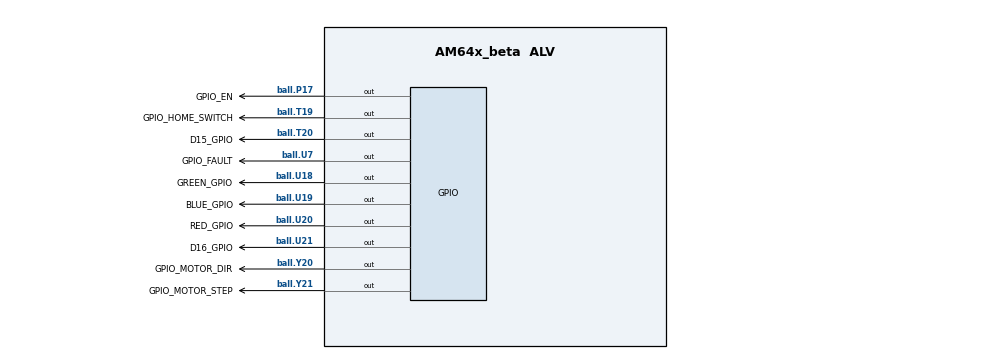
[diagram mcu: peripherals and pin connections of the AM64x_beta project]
/**
 * These arguments were used when this file was generated. They will be automatically applied on subsequent loads
 * via the GUI or CLI. Run CLI with '--help' for additional information on how to override these arguments.
 * @cliArgs --device "AM64x_beta" --package "ALV" --part "Default" --context "r5fss0-0" --product "MCU_PLUS_SDK_AM64x@08.01.00"
 * @versions {"tool":"1.13.0+2553"}
 */

/**
 * Import the modules used in this configuration.
 */
const eeprom     = scripting.addModule("/board/eeprom/eeprom", {}, false);
const eeprom1    = eeprom.addInstance();
const led        = scripting.addModule("/board/led/led", {}, false);
const led1       = led.addInstance();
const led2       = led.addInstance();
const led3       = led.addInstance();
const gpio       = scripting.addModule("/drivers/gpio/gpio", {}, false);
const gpio1      = gpio.addInstance();
const gpio2      = gpio.addInstance();
const gpio3      = gpio.addInstance();
const gpio4      = gpio.addInstance();
const gpio5      = gpio.addInstance();
const gpio6      = gpio.addInstance();
const gpio7      = gpio.addInstance();
const gpio8      = gpio.addInstance();
const gpio9      = gpio.addInstance();
const gpio10     = gpio.addInstance();
const i2c        = scripting.addModule("/drivers/i2c/i2c", {}, false);
const i2c1       = i2c.addInstance();
const i2c2       = i2c.addInstance();
const ipc        = scripting.addModule("/drivers/ipc/ipc");
const ospi       = scripting.addModule("/drivers/ospi/ospi", {}, false);
const ospi1      = ospi.addInstance();
const ethercat   = scripting.addModule("/industrial_comms/ethercat/ethercat", {}, false);
const ethercat1  = ethercat.addInstance();
const debug_log  = scripting.addModule("/kernel/dpl/debug_log");
const mpu_armv7  = scripting.addModule("/kernel/dpl/mpu_armv7", {}, false);
const mpu_armv71 = mpu_armv7.addInstance();
const mpu_armv72 = mpu_armv7.addInstance();
const mpu_armv73 = mpu_armv7.addInstance();
const mpu_armv74 = mpu_armv7.addInstance();
const mpu_armv75 = mpu_armv7.addInstance();
const mpu_armv76 = mpu_armv7.addInstance();

/**
 * Write custom configuration values to the imported modules.
 */
eeprom1.$name = "CONFIG_EEPROM0";

led1.$name = "CONFIG_LED_DIGITAL_OUTPUT";

led2.$name = "CONFIG_LED_RUN";

led3.ioIndex = 16;
led3.$name   = "CONFIG_LED_ERROR";

gpio1.$name                = "GPIO_FAULT";
gpio1.GPIO.gpioPin.$assign = "ball.U7";

gpio2.$name                = "GPIO_HOME_SWITCH";
gpio2.GPIO.gpioPin.$assign = "ball.T19";

gpio3.pinDir               = "OUTPUT";
gpio3.$name                = "GPIO_EN";
gpio3.GPIO.gpioPin.rx      = false;
gpio3.GPIO.gpioPin.$assign = "ball.P17";

gpio4.pinDir               = "OUTPUT";
gpio4.$name                = "GPIO_MOTOR_STEP";
gpio4.GPIO.gpioPin.rx      = false;
gpio4.GPIO.gpioPin.$assign = "ball.Y21";

gpio5.pinDir               = "OUTPUT";
gpio5.$name                = "GPIO_MOTOR_DIR";
gpio5.GPIO.gpioPin.rx      = false;
gpio5.GPIO.gpioPin.$assign = "ball.Y20";

gpio6.$name                = "RED_GPIO";
gpio6.pinDir               = "OUTPUT";
gpio6.GPIO.gpioPin.$assign = "ball.U20";

gpio7.$name                = "GREEN_GPIO";
gpio7.pinDir               = "OUTPUT";
led1.peripheralDriver      = gpio7;
gpio7.GPIO.gpioPin.$assign = "ball.U18";

gpio8.$name                = "BLUE_GPIO";
gpio8.pinDir               = "OUTPUT";
gpio8.GPIO.gpioPin.$assign = "ball.U19";

gpio9.$name                = "D15_GPIO";
gpio9.pinDir               = "OUTPUT";
led2.peripheralDriver      = gpio9;
gpio9.GPIO.gpioPin.rx      = false;
gpio9.GPIO.gpioPin.$assign = "ball.T20";

gpio10.pinDir               = "OUTPUT";
gpio10.$name                = "D16_GPIO";
led3.peripheralDriver       = gpio10;
gpio10.GPIO.gpioPin.rx      = false;
gpio10.GPIO.gpioPin.$assign = "ball.U21";

i2c1.$name               = "CONFIG_I2C0";
eeprom1.peripheralDriver = i2c1;
i2c1.I2C.$assign         = "I2C0";
i2c1.I2C.SCL.$assign     = "ball.A18";
i2c1.I2C.SDA.$assign     = "ball.B18";

i2c2.$name           = "CONFIG_I2C1";
i2c2.I2C.$assign     = "I2C1";
i2c2.I2C.SCL.$assign = "ball.C18";
i2c2.I2C.SDA.$assign = "ball.B19";

ipc.m4fss0_0 = "NONE";

ospi1.$name = "CONFIG_OSPI0";

ethercat1.$name                                 = "CONFIG_ETHERCAT0";
ethercat1.PRU_ICSSG0_IEP.EDC_LATCH_IN0.rx       = false;
ethercat1.PRU_ICSSG0_IEP.EDC_LATCH_IN0.$used    = false;
ethercat1.PRU_ICSSG0_IEP.EDC_LATCH_IN1.rx       = false;
ethercat1.PRU_ICSSG0_IEP.EDC_LATCH_IN1.$used    = false;
ethercat1.PRU_ICSSG0_IEP.EDC_SYNC_OUT0.$used    = false;
ethercat1.PRU_ICSSG0_IEP.EDC_SYNC_OUT1.$used    = false;
ethercat1.PRU_ICSSG0_MII_G_RT.MII0_RXER.pu_pd   = "pd";
ethercat1.PRU_ICSSG0_MII_G_RT.MII0_RXLINK.pu_pd = "pd";
ethercat1.PRU_ICSSG0_MII_G_RT.MII1_RXER.pu_pd   = "pd";
ethercat1.PRU_ICSSG0_MII_G_RT.MII1_RXLINK.pu_pd = "pd";
ethercat1.ethphy[0].$name                       = "CONFIG_ETHPHY0";
ethercat1.ethphy[0].mdioPort                    = 1;
ethercat1.ethphy[1].$name                       = "CONFIG_ETHPHY1";
ethercat1.ethphy[1].mdioPort                    = 2;

const pruicss  = scripting.addModule("/drivers/pruicss/pruicss", {}, false);
const pruicss1 = pruicss.addInstance({}, false);
pruicss1.$name = "CONFIG_PRU_ICSS0";
ethercat1.icss = pruicss1;

debug_log.enableUartLog = true;
debug_log.uartLog.$name = "CONFIG_UART0";

mpu_armv71.$name             = "CONFIG_MPU_REGION0";
mpu_armv71.size              = 31;
mpu_armv71.attributes        = "Device";
mpu_armv71.accessPermissions = "Supervisor RD+WR, User RD";
mpu_armv71.allowExecute      = false;

mpu_armv72.$name             = "CONFIG_MPU_REGION1";
mpu_armv72.size              = 15;
mpu_armv72.accessPermissions = "Supervisor RD+WR, User RD";

mpu_armv73.$name             = "CONFIG_MPU_REGION2";
mpu_armv73.baseAddr          = 0x41010000;
mpu_armv73.size              = 15;
mpu_armv73.accessPermissions = "Supervisor RD+WR, User RD";

mpu_armv74.$name             = "CONFIG_MPU_REGION3";
mpu_armv74.accessPermissions = "Supervisor RD+WR, User RD";
mpu_armv74.baseAddr          = 0x70000000;
mpu_armv74.size              = 21;

mpu_armv75.$name    = "CONFIG_MPU_REGION4";
mpu_armv75.baseAddr = 0x80000000;
mpu_armv75.size     = 31;

mpu_armv76.$name      = "CONFIG_MPU_REGION5";
mpu_armv76.baseAddr   = 0x701D0000;
mpu_armv76.size       = 16;
mpu_armv76.attributes = "Device";

/**
 * Pinmux solution for unlocked pins/peripherals. This ensures that minor changes to the automatic solver in a future
 * version of the tool will not impact the pinmux you originally saw.  These lines can be completely deleted in order to
 * re-solve from scratch.
 */
gpio1.GPIO.$suggestSolution                                = "GPIO0";
gpio2.GPIO.$suggestSolution                                = "GPIO0";
gpio3.GPIO.$suggestSolution                                = "GPIO0";
gpio4.GPIO.$suggestSolution                                = "GPIO0";
gpio5.GPIO.$suggestSolution                                = "GPIO0";
gpio6.GPIO.$suggestSolution                                = "GPIO0";
gpio7.GPIO.$suggestSolution                                = "GPIO0";
gpio8.GPIO.$suggestSolution                                = "GPIO0";
gpio9.GPIO.$suggestSolution                                = "GPIO0";
gpio10.GPIO.$suggestSolution                               = "GPIO0";
ospi1.OSPI.$suggestSolution                                = "OSPI0";
ospi1.OSPI.CLK.$suggestSolution                            = "ball.N20";
ospi1.OSPI.CSn0.$suggestSolution                           = "ball.L19";
ospi1.OSPI.DQS.$suggestSolution                            = "ball.N19";
ospi1.OSPI.D7.$suggestSolution                             = "ball.M17";
ospi1.OSPI.D6.$suggestSolution                             = "ball.N18";
ospi1.OSPI.D5.$suggestSolution                             = "ball.P20";
ospi1.OSPI.D4.$suggestSolution                             = "ball.P21";
ospi1.OSPI.D3.$suggestSolution                             = "ball.M21";
ospi1.OSPI.D2.$suggestSolution                             = "ball.M20";
ospi1.OSPI.D1.$suggestSolution                             = "ball.M18";
ospi1.OSPI.D0.$suggestSolution                             = "ball.M19";
ethercat1.PRU_ICSSG0_MDIO.$suggestSolution                 = "PRU_ICSSG0_MDIO0";
ethercat1.PRU_ICSSG0_MDIO.MDC.$suggestSolution             = "ball.P3";
ethercat1.PRU_ICSSG0_MDIO.MDIO.$suggestSolution            = "ball.P2";
ethercat1.PRU_ICSSG0_IEP.$suggestSolution                  = "PRU_ICSSG0_IEP0";
ethercat1.PRU_ICSSG0_MII_G_RT.$suggestSolution             = "PRU_ICSSG0_MII_G_RT";
ethercat1.PRU_ICSSG0_MII_G_RT.MII0_RXD0.$suggestSolution   = "ball.Y1";
ethercat1.PRU_ICSSG0_MII_G_RT.MII0_RXD1.$suggestSolution   = "ball.R4";
ethercat1.PRU_ICSSG0_MII_G_RT.MII0_RXD2.$suggestSolution   = "ball.U2";
ethercat1.PRU_ICSSG0_MII_G_RT.MII0_RXD3.$suggestSolution   = "ball.V2";
ethercat1.PRU_ICSSG0_MII_G_RT.MII0_RXDV.$suggestSolution   = "ball.AA2";
ethercat1.PRU_ICSSG0_MII_G_RT.MII0_RXER.$suggestSolution   = "ball.R3";
ethercat1.PRU_ICSSG0_MII_G_RT.MII0_RXLINK.$suggestSolution = "ball.T2";
ethercat1.PRU_ICSSG0_MII_G_RT.MII0_TXD0.$suggestSolution   = "ball.Y3";
ethercat1.PRU_ICSSG0_MII_G_RT.MII0_TXD1.$suggestSolution   = "ball.AA3";
ethercat1.PRU_ICSSG0_MII_G_RT.MII0_TXD2.$suggestSolution   = "ball.R6";
ethercat1.PRU_ICSSG0_MII_G_RT.MII0_TXD3.$suggestSolution   = "ball.V4";
ethercat1.PRU_ICSSG0_MII_G_RT.MII0_TXEN.$suggestSolution   = "ball.T5";
ethercat1.PRU_ICSSG0_MII_G_RT.MII1_RXD0.$suggestSolution   = "ball.Y2";
ethercat1.PRU_ICSSG0_MII_G_RT.MII1_RXD1.$suggestSolution   = "ball.W2";
ethercat1.PRU_ICSSG0_MII_G_RT.MII1_RXD2.$suggestSolution   = "ball.V3";
ethercat1.PRU_ICSSG0_MII_G_RT.MII1_RXD3.$suggestSolution   = "ball.T4";
ethercat1.PRU_ICSSG0_MII_G_RT.MII1_RXDV.$suggestSolution   = "ball.W3";
ethercat1.PRU_ICSSG0_MII_G_RT.MII1_RXER.$suggestSolution   = "ball.P4";
ethercat1.PRU_ICSSG0_MII_G_RT.MII1_RXLINK.$suggestSolution = "ball.R1";
ethercat1.PRU_ICSSG0_MII_G_RT.MII1_TXD0.$suggestSolution   = "ball.W4";
ethercat1.PRU_ICSSG0_MII_G_RT.MII1_TXD1.$suggestSolution   = "ball.Y4";
ethercat1.PRU_ICSSG0_MII_G_RT.MII1_TXD2.$suggestSolution   = "ball.T6";
ethercat1.PRU_ICSSG0_MII_G_RT.MII1_TXD3.$suggestSolution   = "ball.U6";
ethercat1.PRU_ICSSG0_MII_G_RT.MII1_TXEN.$suggestSolution   = "ball.U5";
ethercat1.PRU_ICSSG0_MII_G_RT.MII_MR0_CLK.$suggestSolution = "ball.T3";
ethercat1.PRU_ICSSG0_MII_G_RT.MII_MR1_CLK.$suggestSolution = "ball.R5";
ethercat1.PRU_ICSSG0_MII_G_RT.MII_MT0_CLK.$suggestSolution = "ball.U4";
ethercat1.PRU_ICSSG0_MII_G_RT.MII_MT1_CLK.$suggestSolution = "ball.AA4";
debug_log.uartLog.UART.$suggestSolution                    = "USART0";
debug_log.uartLog.UART.RXD.$suggestSolution                = "ball.D15";
debug_log.uartLog.UART.TXD.$suggestSolution                = "ball.C16";
